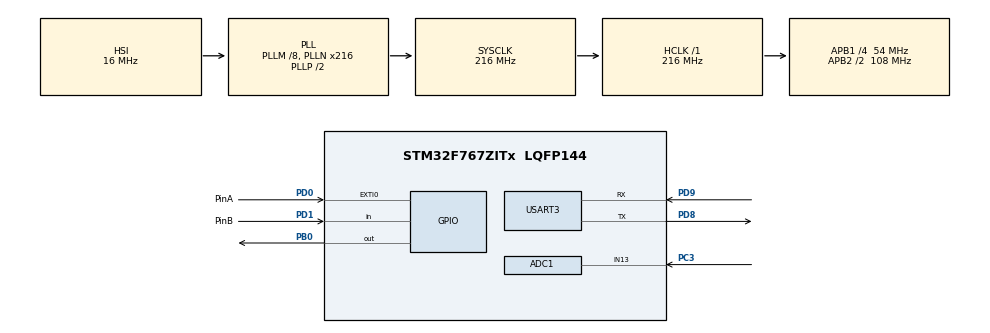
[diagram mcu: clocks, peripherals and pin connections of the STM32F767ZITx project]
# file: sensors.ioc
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Mcu.Family=STM32F7
NVIC.USART3_IRQn=true\:0\:0\:false\:false\:true\:true\:true
SH.ADCx_IN13.0=ADC1_IN13,IN13
RCC.CortexFreq_Value=216000000
ADC1.ContinuousConvMode=DISABLE
TIM6.Prescaler=863
VP_TIM6_VS_ClockSourceINT.Mode=Enable_Timer
PD0.GPIO_Label=PinA
PD1.Signal=GPIO_Input
PD9.Signal=USART3_RX
RCC.APB1CLKDivider=RCC_HCLK_DIV4
PD9.Mode=Asynchronous
RCC.SYSCLKSource=RCC_SYSCLKSOURCE_PLLCLK
ProjectManager.StackSize=0x400
USART3.VirtualMode-Asynchronous=VM_ASYNC
TIM6.AutoReloadPreload=TIM_AUTORELOAD_PRELOAD_ENABLE
NVIC.ADC_IRQn=true\:0\:0\:false\:false\:true\:true\:true
ProjectManager.TargetToolchain=STM32CubeIDE
RCC.HCLKFreq_Value=216000000
RCC.APB2TimFreq_Value=216000000
ADC1.Channel-1\#ChannelRegularConversion=ADC_CHANNEL_13
PC3.Signal=ADCx_IN13
PD0.Signal=GPXTI0
PD8.Signal=USART3_TX
RCC.USBFreq_Value=216000000
RCC.LSE_VALUE=32768
PD8.Mode=Asynchronous
RCC.AHBFreq_Value=216000000
RCC.HSE_VALUE=25000000
board=custom
RCC.VCOOutputFreq_Value=432000000
PD1.GPIO_Label=PinB
RCC.APB2Freq_Value=108000000
TIM6.TIM_MasterOutputTrigger=TIM_TRGO_UPDATE
TIM6.Period=62499
ADC1.NbrOfConversion=1
Mcu.Name=STM32F767ZITx
ADC1.ExternalTrigConv=ADC_EXTERNALTRIGCONV_T6_TRGO
NVIC.EXTI0_IRQn=true\:0\:0\:false\:false\:true\:true\:true
ADC1.SamplingTime-1\#ChannelRegularConversion=ADC_SAMPLETIME_3CYCLES
RCC.SYSCLKFreq_VALUE=216000000
Mcu.Package=LQFP144
ADC1.master=1
ADC1.Rank-1\#ChannelRegularConversion=1
ProjectManager.HeapSize=0x200
RCC.HSI_VALUE=16000000
NVIC.PriorityGroup=NVIC_PRIORITYGROUP_4
ADC1.NbrOfConversionFlag=1
RCC.APB2CLKDivider=RCC_HCLK_DIV2
RCC.PLLM=8
RCC.PLLN=216
RCC.APB1TimFreq_Value=108000000
RCC.APB1Freq_Value=54000000
PB0.Signal=GPIO_Output
ADC1.EOCSelection=ADC_EOC_SEQ_CONV

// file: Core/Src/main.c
/* USER CODE BEGIN Header */
/**
  ******************************************************************************
  * @file           : main.c
  * @brief          : Main program body
  ******************************************************************************
  * @attention
  *
  * <h2><center>&copy; Copyright (c) 2021 STMicroelectronics.
  * All rights reserved.</center></h2>
  *
  * This software component is licensed by ST under BSD 3-Clause license,
  * the "License"; You may not use this file except in compliance with the
  * License. You may obtain a copy of the License at:
  *                        opensource.org/licenses/BSD-3-Clause
  *
  ******************************************************************************
  */
/* USER CODE END Header */
#include "main.h"
#include "adc.h"
#include "tim.h"
#include "usart.h"
#include "gpio.h"

/* USER CODE BEGIN Includes */
#include "stop_sensors.h"

/* USER CODE END Includes */

void SystemClock_Config(void);

int main(void)
{

  /* MCU Configuration--------------------------------------------------------*/

  /* Reset of all peripherals, Initializes the Flash interface and the Systick. */
  HAL_Init();

  /* Configure the system clock */
  SystemClock_Config();

  /* Initialize all configured peripherals */
  MX_GPIO_Init();
  MX_ADC1_Init();
  MX_TIM6_Init();
  MX_USART3_UART_Init();
  /* USER CODE BEGIN 2 */
  //Rx_UART_init(); // set USART3 interrupt

  stop_sensors_init();
  /* USER CODE END 2 */

  /* Infinite loop */
  /* USER CODE BEGIN WHILE */
  UART_puts("Hello STM32: stop sensors.\n\r");
  while (1)
  {

    /* USER CODE END WHILE */

  }
}

void SystemClock_Config(void)
{
  RCC_OscInitTypeDef RCC_OscInitStruct = {0};
  RCC_ClkInitTypeDef RCC_ClkInitStruct = {0};
  RCC_PeriphCLKInitTypeDef PeriphClkInitStruct = {0};

  /** Configure the main internal regulator output voltage
  */
  __HAL_RCC_PWR_CLK_ENABLE();
  __HAL_PWR_VOLTAGESCALING_CONFIG(PWR_REGULATOR_VOLTAGE_SCALE1);
  /** Initializes the RCC Oscillators according to the specified parameters
  * in the RCC_OscInitTypeDef structure.
  */
  RCC_OscInitStruct.OscillatorType = RCC_OSCILLATORTYPE_HSI;
  RCC_OscInitStruct.HSIState = RCC_HSI_ON;
  RCC_OscInitStruct.HSICalibrationValue = RCC_HSICALIBRATION_DEFAULT;
  RCC_OscInitStruct.PLL.PLLState = RCC_PLL_ON;
  RCC_OscInitStruct.PLL.PLLSource = RCC_PLLSOURCE_HSI;
  RCC_OscInitStruct.PLL.PLLM = 8;
  RCC_OscInitStruct.PLL.PLLN = 216;
  RCC_OscInitStruct.PLL.PLLP = RCC_PLLP_DIV2;
  RCC_OscInitStruct.PLL.PLLQ = 2;
  if (HAL_RCC_OscConfig(&RCC_OscInitStruct) != HAL_OK)
  {
    Error_Handler();
  }
  /** Activate the Over-Drive mode
  */
  if (HAL_PWREx_EnableOverDrive() != HAL_OK)
  {
    Error_Handler();
  }
  /** Initializes the CPU, AHB and APB buses clocks
  */
  RCC_ClkInitStruct.ClockType = RCC_CLOCKTYPE_HCLK|RCC_CLOCKTYPE_SYSCLK
                              |RCC_CLOCKTYPE_PCLK1|RCC_CLOCKTYPE_PCLK2;
  RCC_ClkInitStruct.SYSCLKSource = RCC_SYSCLKSOURCE_PLLCLK;
  RCC_ClkInitStruct.AHBCLKDivider = RCC_SYSCLK_DIV1;
  RCC_ClkInitStruct.APB1CLKDivider = RCC_HCLK_DIV4;
  RCC_ClkInitStruct.APB2CLKDivider = RCC_HCLK_DIV2;

  if (HAL_RCC_ClockConfig(&RCC_ClkInitStruct, FLASH_LATENCY_7) != HAL_OK)
  {
    Error_Handler();
  }
  PeriphClkInitStruct.PeriphClockSelection = RCC_PERIPHCLK_USART3;
  PeriphClkInitStruct.Usart3ClockSelection = RCC_USART3CLKSOURCE_PCLK1;
  if (HAL_RCCEx_PeriphCLKConfig(&PeriphClkInitStruct) != HAL_OK)
  {
    Error_Handler();
  }
}

void Error_Handler(void)
{
  __disable_irq();
  while (1)
  {
  }
}

/************************ (C) COPYRIGHT STMicroelectronics *****END OF FILE****/
